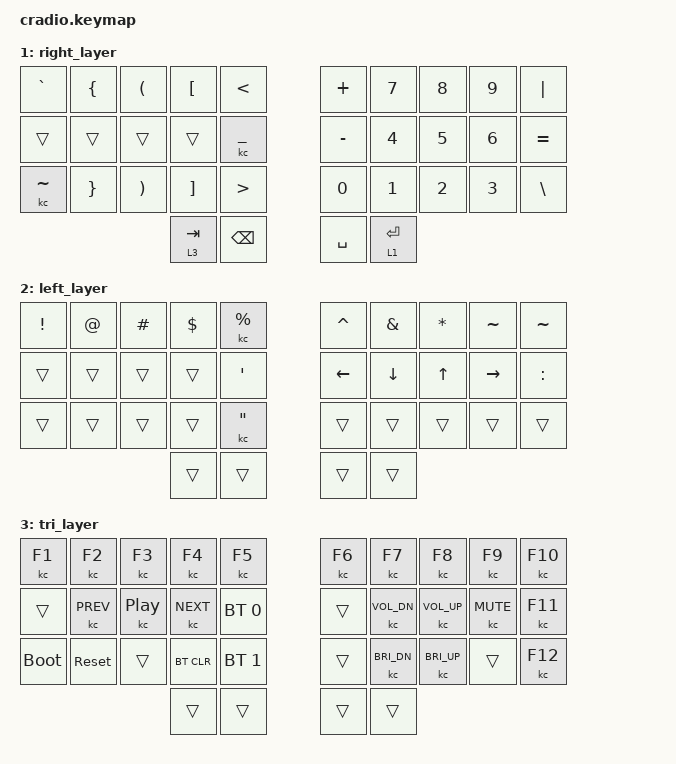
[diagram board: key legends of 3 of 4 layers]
// Copyright (c) 2022 The ZMK Contributors
// SPDX-License-Identifier: MIT

#include <behaviors.dtsi>
#include <dt-bindings/zmk/keys.h>
#include <dt-bindings/zmk/bt.h>

// Home row mods macro
#define HRML(k1,k2,k3,k4) &ht LCTRL k1  &ht LALT k2  &ht LGUI k3  &ht LSHFT k4
#define HRMR(k1,k2,k3,k4) &ht RCTRL k1  &ht RALT k2  &ht RGUI k3  &ht RSHFT k4

// Keycode macros
#define KCOPY &ht LGUI(C) C
#define KPASTE &ht LGUI(V) V
#define KCUT &ht LGUI(X) X

/ {
    behaviors {
        ht: hold_tap {
            compatible = "zmk,behavior-hold-tap";
            #binding-cells = <2>;
            flavor = "tap-preferred";
            tapping-term-ms = <220>;
            quick-tap-ms = <150>;
            require-prior-idle-ms = <100>;
            bindings = <&kp>, <&kp>;
        };
    };

    combos {
        compatible = "zmk,combos";
        combo_enter {
            timeout-ms = <50>;
            key-positions = <31 32>;
            bindings = <&kp RET>;
        };
        combo_escl {
            timeout-ms = <50>;
            key-positions = <12 13>;
            bindings = <&kp ESC>;
        };
        combo_escr {
            timeout-ms = <50>;
            key-positions = <16 17>;
            bindings = <&kp ESC>;
        };
        combo_caps {
            timeout-ms = <50>;
            key-positions = <6 7>;
            bindings = <&kp CAPS>;
        };
    };

    conditional_layers {
        compatible = "zmk,conditional-layers";
        tri_layer {
            if-layers = <1 2>;
            then-layer = <3>;
        };
    };

    keymap {
        compatible = "zmk,keymap";
        default_layer {
            bindings = <
        //╭──────────┬──────────┬──────────┬──────────┬──────────╮   ╭──────────┬──────────┬──────────┬──────────┬──────────╮
        //│  Q       │  W       │  E       │  R       │  T       │   │  Y       │  U       │  I       │  O       │  P       │
            &kp Q      &kp W      &kp E      &kp R      &kp T          &kp Y      &kp U      &kp I      &kp O      &kp P
        //├──────────┼──────────┼──────────┼──────────┼──────────┤   ├──────────┼──────────┼──────────┼──────────┼──────────┤
        //│  A       │  S       │  D       │  F       │  G       │   │  H       │  J       │  K       │  L       │ ; :      │
            HRML(A,        S,         D,         F)     &kp G          &kp H      HRMR(J,        K,         L,       SEMI)
        //├──────────┼──────────┼──────────┼──────────┼──────────┤   ├──────────┼──────────┼──────────┼──────────┼──────────┤
        //│  Z       │  X       │  C       │  V       │  B       │   │  N       │  M       │ , <      │ . >      │ / ?      │
            &kp Z      KCUT       KCOPY      KPASTE     &kp B          &kp N      &kp M      &kp COMMA  &kp DOT    &kp FSLH
        //╰──────────┴──────────┴──────────┼──────────┼──────────┤   ├──────────┼──────────┼──────────┴──────────┴──────────╯
                                             &lt 2 TAB  &kp BSPC       &kp SPACE  &lt 1 ENTER
        //                                 ╰──────────┴──────────╯   ╰──────────┴──────────╯
            >;
        };

        right_layer {
            bindings = <
        //╭──────────┬──────────┬──────────┬──────────┬──────────╮   ╭──────────┬──────────┬──────────┬──────────┬──────────╮
        //│  ` ~     │  {       │  (       │  [       │  <       │   │  +       │  7 &     │  8 *     │  9 (     │  |       │
            &kp GRAVE  &kp LBRC   &kp LPAR   &kp LBKT   &kp LT         &kp PLUS   &kp N7     &kp N8     &kp N9     &kp PIPE
        //├──────────┼──────────┼──────────┼──────────┼──────────┤   ├──────────┼──────────┼──────────┼──────────┼──────────┤
        //│          │          │          │          │  _       │   │  - _     │  4 $     │  5 %     │  6 ^     │  = +     │
            &trans     &trans     &trans     &trans     &kc UNDER      &kp MINUS  &kp N4     &kp N5     &kp N6     &kp EQUAL
        //├──────────┼──────────┼──────────┼──────────┼──────────┤   ├──────────┼──────────┼──────────┼──────────┼──────────┤
        //│  ~       │  }       │  )       │  ]       │  >       │   │  0 )     │  1 !     │  2 @     │  3 #     │  \ |     │
            &kc TILDE  &kp RBRC   &kp RPAR   &kp RBKT   &kp GT         &kp N0     &kp N1     &kp N2     &kp N3     &kp BSLH
        //╰──────────┴──────────┴──────────┼──────────┼──────────┤   ├──────────┼──────────┼──────────┴──────────┴──────────╯
                                             &lt 3 TAB  &kp BSPC       &kp SPACE  &lt 1 ENTER
        //                                 ╰──────────┴──────────╯   ╰──────────┴──────────╯
            >;
        };

        left_layer {
            bindings = <
        //╭──────────┬──────────┬──────────┬──────────┬──────────╮   ╭──────────┬──────────┬──────────┬──────────┬──────────╮
        //│  !       │  @       │  #       │  $       │  %       │   │  ^       │  &       │  *       │  ~       │  ~       │
            &kp EXCL   &kp AT     &kp HASH   &kp DLLR   &kc PRCNT      &kp CARET  &kp AMPS   &kp ASTRK  &kp TILDE  &kp TILDE
        //├──────────┼──────────┼──────────┼──────────┼──────────┤   ├──────────┼──────────┼──────────┼──────────┼──────────┤
        //│          │          │          │          │  ' "     │   │          │          │          │          │  :       │
            &trans     &trans     &trans     &trans     &kp SQT        &kp LEFT   &kp DOWN   &kp UP     &kp RIGHT  &kp COLON
        //├──────────┼──────────┼──────────┼──────────┼──────────┤   ├──────────┼──────────┼──────────┼──────────┼──────────┤
        //│          │          │          │          │  "       │   │          │          │          │          │          │
            &trans     &trans     &trans     &trans     &kc DQT        &trans     &trans     &trans     &trans     &trans
        //╰──────────┴──────────┴──────────┼──────────┼──────────┤   ├──────────┼──────────┼──────────┴──────────┴──────────╯
                                             &trans     &trans         &trans     &trans
        //                                 ╰──────────┴──────────╯   ╰──────────┴──────────╯
            >;
        };

        tri_layer {
            bindings = <
        //╭──────────┬──────────┬──────────┬──────────┬──────────╮   ╭──────────┬──────────┬──────────┬──────────┬──────────╮
        //│          │          │          │          │          │   │          │          │          │          │          │
            &kc F1     &kc F2     &kc F3     &kc F4     &kc F5         &kc F6     &kc F7     &kc F8     &kc F9     &kc F10
        //├──────────┼──────────┼──────────┼──────────┼──────────┤   ├──────────┼──────────┼──────────┼──────────┼──────────┤
        //│          │          │          │          │PROFILE 0 │   │          │          │          │          │          │
           &trans      &kc C_PREV &kc C_PP   &kc C_NEXT &bt BT_SEL 0    &trans   &kc C_VOL_DN &kc C_VOL_UP &kc K_MUTE &kc F11
        //├──────────┼──────────┼──────────┼──────────┼──────────┤   ├──────────┼──────────┼──────────┼──────────┼──────────┤
        //│BOOTLOADER│ RESET    │          │ CLEAR BT │PROFILE 1 │   │          │          │          │          │          │
          &bootloader &sys_reset  &trans    &bt BT_CLR &bt BT_SEL 1    &trans   &kc C_BRI_DN &kc C_BRI_UP &trans   &kc F12
        //╰──────────┴──────────┴──────────┼──────────┼──────────┤   ├──────────┼──────────┼──────────┴──────────┴──────────╯
                                             &trans     &trans         &trans     &trans
        //                                 ╰──────────┴──────────╯   ╰──────────┴──────────╯
            >;
        };
    };
};
